# STM32U5G7xx register map
File version: 1.0
Registers are 32-bit, read-write, reset 0x0 unless marked. A register's access mark holds for its fields unless they carry their own. Offsets are from the block's base; [hi:lo] are bit positions; {n}, {i} and the like mark numbered series.

## TIM1 — TIM
Base 0x40012C00
Same registers: TIM1_S 0x50012C00
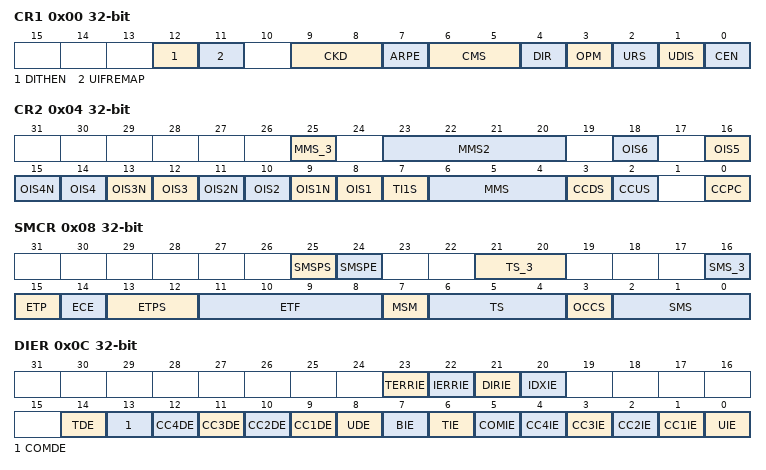
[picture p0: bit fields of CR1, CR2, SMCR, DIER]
0x00 CR1 — TIM control register 1
  [12] DITHEN — Dithering enable
  [11] UIFREMAP — Update interrupt flag remap
  [9:8] CKD — CKD[1:0] bits (clock division)
    0=DIV1 (tDTS=tCK_INT); 1=DIV2 (tDTS=2*tCK_INT); 2=DIV4 (tDTS=4*tCK_INT)
  [7] ARPE — Auto-reload preload enable
  [6:5] CMS — CMS[1:0] bits (Center-aligned mode selection)
  [4] DIR — Direction
    0=UP (Timer counter counts up); 1=DOWN (Timer counter counts down)
  [3] OPM — One pulse mode
    1=SINGLE (Counter stops counting at the next update event); 0=REPETITIVE (Counter is not stopped at update event)
  [2] URS — Update request source
    0=REGULAR (Counter overflow/underflow, Setting the UG bit or Update generation through the slave mode controller generates an update request); 1=COUNTER (Only counter overflow/underflow generates an update request)
  [1] UDIS — Update disable
  [0] CEN — Counter enable
0x04 CR2 — TIM control register 2
  [25] MMS_3 — MMS[3:0] bits (Master Mode Selection)
  [23:20] MMS2 — MMS[2:0] bits (Master Mode Selection)
    0=RESET (UG bit from the TIMx_EGR register is used as trigger output 2); 1=ENABLE (Counter Enable signal (CNT_EN) is used as trigger output 2); 2=UPDATE (Update event is used as trigger output 2); 3=CC1F (CC1 capture or a compare match is used as trigger output 2); {v}=OC{v-3} (OC{v-3}REF signal is used as trigger output 2) (v=4..9); 10=OC4_RISINGFALLING (OC4REF rising or falling edges are used as trigger output 2); 11=OC6_RISINGFALLING (OC6REF rising or falling edges are used as trigger output 2); 12=OC4_RISING_OC6_RISING (OC4REF or OC6REF rising edges are used as trigger output 2); 13=OC4_RISING_OC6_FALLING (OC4REF rising or OC6REF falling edges are used as trigger output 2); 14=OC5_RISING_OC6_RISING (OC5REF or OC6REF rising edges are used as trigger output 2); 15=OC5_RISING_OC6_FALLING (OC5REF rising or OC6REF falling edges are used as trigger output 2)
  [2n+6] OIS{n} (n=1..6) — Output Idle state {n} (OC{n} output)
  [2n+7] OIS{n}N (n=1..4) — Output Idle state {n} (OC{n}N output)
  [7] TI1S — TI1 Selection
  [6:4] MMS — MMS[3:0] bits (Master Mode Selection)
  [3] CCDS — Capture/Compare DMA Selection
    0=CC (CCx DMA request sent when CCx event occurs); 1=UPDATE (CCx DMA requests sent when update event occurs)
  [2] CCUS — Capture/Compare Control Update Selection
    0=ONLY (Capture/compare control bits are updated by setting the COMG bit only); 1=AND_TRGI (Capture/compare control bits are updated by setting the COMG bit or when a rising edge occurs on trigger input (TRGI))
  [0] CCPC — Capture/Compare Preloaded Control
0x08 SMCR — TIM slave mode control register
  [25] SMSPS — SMS preload source
    0=TIMUPDATE (The SMS preload transfer is triggered by the Timer's Update event); 1=INDEX (The SMS preload transfer is triggered by the Index event)
  [24] SMSPE — SMS preload enable
  [21:20] TS_3 — TS[2:0] bits (Trigger selection)
  [16] SMS_3 — SMS[2:0] bits (Slave mode selection)
  [15] ETP — External trigger polarity
  [14] ECE — External clock enable
  [13:12] ETPS — ETPS[1:0] bits (External trigger prescaler)
  [11:8] ETF — ETF[3:0] bits (External trigger filter)
  [7] MSM — Master/slave mode
  [6:4] TS — TS[2:0] bits (Trigger selection)
  [3] OCCS — OCREF clear selection
  [2:0] SMS — SMS[2:0] bits (Slave mode selection)
0x0C DIER — TIM DMA/interrupt enable register
  [23] TERRIE — Encoder transition error enable
  [22] IERRIE — Encoder index error enable
  [21] DIRIE — Encoder direction change interrupt enable
  [20] IDXIE — Encoder index interrupt enable
  [14] TDE — Trigger DMA request enable
  [13] COMDE — COM DMA request enable
  [n+8] CC{n}DE (n=1..4) — Capture/Compare {n} DMA request enable
  [8] UDE — Update DMA request enable
  [7] BIE — Break interrupt enable
  [6] TIE — Trigger interrupt enable
  [5] COMIE — COM interrupt enable
  [n] CC{n}IE (n=1..4) — Capture/Compare {n} interrupt enable
  [0] UIE — Update interrupt enable
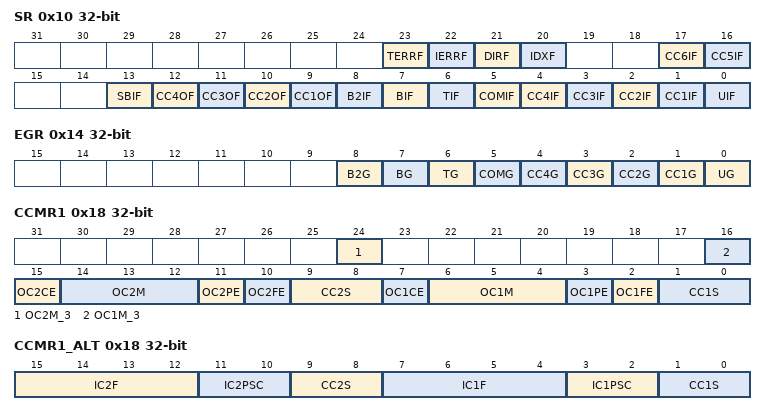
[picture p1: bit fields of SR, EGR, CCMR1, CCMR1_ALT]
0x10 SR — TIM status register
  [23] TERRF — Encoder transition error flag
  [22] IERRF — Encoder index error flag
  [21] DIRF — Encoder direction change interrupt flag
  [20] IDXF — Encoder index interrupt flag
  [17] CC6IF — Capture/Compare 6 interrupt Flag
  [16] CC5IF — Capture/Compare 5 interrupt Flag
  [13] SBIF — System Break interrupt Flag
  [n+8] CC{n}OF (n=1..4) — Capture/Compare {n} Overcapture Flag
  [8] B2IF — Break 2 interrupt Flag
  [7] BIF — Break interrupt Flag
  [6] TIF — Trigger interrupt Flag
  [5] COMIF — COM interrupt Flag
  [n] CC{n}IF (n=1..4) — Capture/Compare {n} interrupt Flag
  [0] UIF — Update interrupt Flag
0x14 EGR — TIM event generation register
  [8] B2G — Break 2 Generation
  [7] BG — Break Generation
  [6] TG — Trigger Generation
  [5] COMG — Capture/Compare Control Update Generation
  [n] CC{n}G (n=1..4) — Capture/Compare {n} Generation
  [0] UG — Update Generation
0x18 CCMR1 — TIM capture/compare mode register 1
  [24] OC2M_3 — OC2M[2:0] bits (Output Compare 2 Mode)
  [16] OC1M_3 — OC1M[2:0] bits (Output Compare 1 Mode)
  [15] OC2CE — Output Compare 2 Clear Enable
  [14:12] OC2M — OC2M[2:0] bits (Output Compare 2 Mode)
  [11] OC2PE — Output Compare 2 Preload enable
  [10] OC2FE — Output Compare 2 Fast enable
  [9:8] CC2S — CC2S[1:0] bits (Capture/Compare 2 Selection)
  [7] OC1CE — Output Compare 1 Clear Enable
  [6:4] OC1M — OC1M[2:0] bits (Output Compare 1 Mode)
  [3] OC1PE — Output Compare 1 Preload enable
  [2] OC1FE — Output Compare 1 Fast enable
  [1:0] CC1S — CC1S[1:0] bits (Capture/Compare 1 Selection)
0x18 CCMR1_ALT (alternate view of CCMR1) — TIM capture/compare mode register 1
  [15:12] IC2F — IC2F[3:0] bits (Input Capture 2 Filter)
  [11:10] IC2PSC — IC2PSC[1:0] bits (Input Capture 2 Prescaler)
  [9:8] CC2S — CC2S[1:0] bits (Capture/Compare 2 Selection)
  [7:4] IC1F — IC1F[3:0] bits (Input Capture 1 Filter)
  [3:2] IC1PSC — IC1PSC[1:0] bits (Input Capture 1 Prescaler)
  [1:0] CC1S — CC1S[1:0] bits (Capture/Compare 1 Selection)
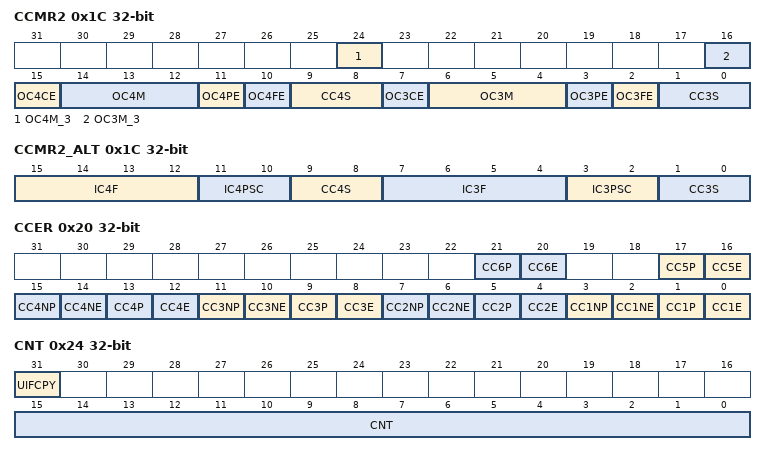
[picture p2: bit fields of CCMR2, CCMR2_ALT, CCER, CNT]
0x1C CCMR2 — TIM capture/compare mode register 2
  [24] OC4M_3 — OC4M[2:0] bits (Output Compare 4 Mode)
  [16] OC3M_3 — OC3M[2:0] bits (Output Compare 3 Mode)
  [15] OC4CE — Output Compare 4 Clear Enable
  [14:12] OC4M — OC4M[2:0] bits (Output Compare 4 Mode)
  [11] OC4PE — Output Compare 4 Preload enable
  [10] OC4FE — Output Compare 4 Fast enable
  [9:8] CC4S — CC4S[1:0] bits (Capture/Compare 4 Selection)
  [7] OC3CE — Output Compare 3 Clear Enable
  [6:4] OC3M — OC3M[2:0] bits (Output Compare 3 Mode)
  [3] OC3PE — Output Compare 3 Preload enable
  [2] OC3FE — Output Compare 3 Fast enable
  [1:0] CC3S — CC3S[1:0] bits (Capture/Compare 3 Selection)
0x1C CCMR2_ALT (alternate view of CCMR2) — TIM capture/compare mode register 2
  [15:12] IC4F — IC4F[3:0] bits (Input Capture 4 Filter)
  [11:10] IC4PSC — IC4PSC[1:0] bits (Input Capture 4 Prescaler)
  [9:8] CC4S — CC4S[1:0] bits (Capture/Compare 4 Selection)
  [7:4] IC3F — IC3F[3:0] bits (Input Capture 3 Filter)
  [3:2] IC3PSC — IC3PSC[1:0] bits (Input Capture 3 Prescaler)
  [1:0] CC3S — CC3S[1:0] bits (Capture/Compare 3 Selection)
0x20 CCER — TIM capture/compare enable register
  [4n-3] CC{n}P (n=1..6) — Capture/Compare {n} output Polarity
  [4n-4] CC{n}E (n=1..6) — Capture/Compare {n} output enable
  [4n-1] CC{n}NP (n=1..4) — Capture/Compare {n} Complementary output Polarity
  [4n-2] CC{n}NE (n=1..4) — Capture/Compare {n} Complementary output enable
0x24 CNT — TIM counter register
  [31] UIFCPY — Update interrupt flag copy (if UIFREMAP=1)
  [15:0] CNT — Counter Value
0x28 PSC — TIM prescaler
  [15:0] PSC — Prescaler Value
0x2C ARR — TIM auto-reload register
  [15:0] ARR — Actual auto-reload Value
0x30 RCR — TIM repetition counter register
  [15:0] REP — Repetition Counter Value
{0x30+4i} CCR{i} (i=1..4) — TIM capture/compare register {i}
  [15:0] CCR{i} — Capture/Compare {i} Value
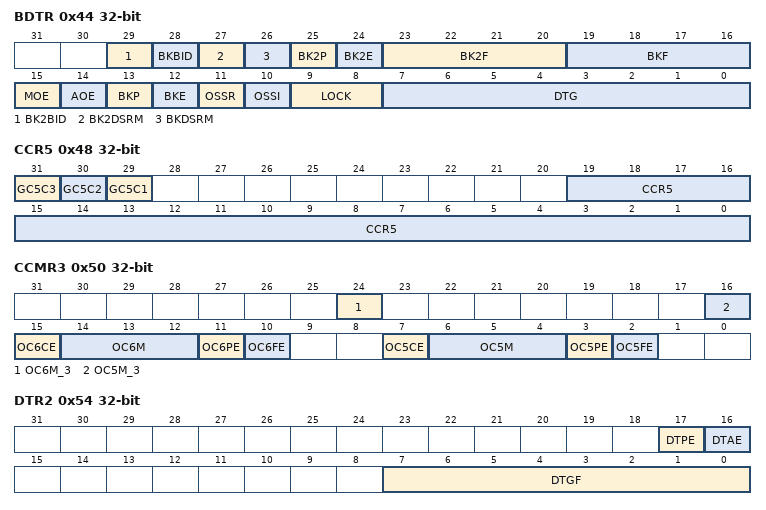
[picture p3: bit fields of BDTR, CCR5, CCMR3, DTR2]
0x44 BDTR — TIM break and dead-time register
  [29] BK2BID — Break2 BIDirectional
  [28] BKBID — Break BIDirectional
  [27] BK2DSRM — Break2 disarming/re-arming
  [26] BKDSRM — Break disarming/re-arming
  [25] BK2P — Break Polarity for Break 2
  [24] BK2E — Break enable for Break 2
  [23:20] BK2F — Break Filter for Break 2
  [19:16] BKF — Break Filter for Break 1
  [15] MOE — Main Output enable
  [14] AOE — Automatic Output enable
  [13] BKP — Break Polarity for Break 1
  [12] BKE — Break enable for Break 1
  [11] OSSR — Off-State Selection for Run mode
  [10] OSSI — Off-State Selection for Idle mode
  [9:8] LOCK — LOCK[1:0] bits (Lock Configuration)
    0=OFF (LOCK OFF - No bit is write protected); 1=LOCKLEVEL_1; 2=LOCKLEVEL_2; 3=LOCKLEVEL_3
  [7:0] DTG — DTG[0:7] bits (Dead-Time Generator set-up)
0x48 CCR5 — TIM capture/compare register 5
  [31] GC5C3 — Group Channel 5 and Channel 3
  [30] GC5C2 — Group Channel 5 and Channel 2
  [29] GC5C1 — Group Channel 5 and Channel 1
  [19:0] CCR5 — Capture/Compare 5 Value
0x4C CCR6 — TIM capture/compare register 6
  [19:0] CCR6 — Capture/Compare 6 Value
0x50 CCMR3 — TIM capture/compare mode register 3
  [24] OC6M_3 — OC6M[3:0] bits (Output Compare 6 Mode)
  [16] OC5M_3 — OC5M[3:0] bits (Output Compare 5 Mode)
  [15] OC6CE — Output Compare 6 Clear Enable
  [14:12] OC6M — OC6M[3:0] bits (Output Compare 6 Mode)
  [11] OC6PE — Output Compare 6 Preload enable
  [10] OC6FE — Output Compare 6 Fast enable
  [7] OC5CE — Output Compare 5 Clear Enable
  [6:4] OC5M — OC5M[3:0] bits (Output Compare 5 Mode)
  [3] OC5PE — Output Compare 5 Preload enable
  [2] OC5FE — Output Compare 5 Fast enable
0x54 DTR2 — TIM deadtime register 2
  [17] DTPE — Deadtime prelaod enable
  [16] DTAE — Deadtime asymmetric enable
  [7:0] DTGF — DTGF[7:0] bits (Deadtime falling edge generator setup)
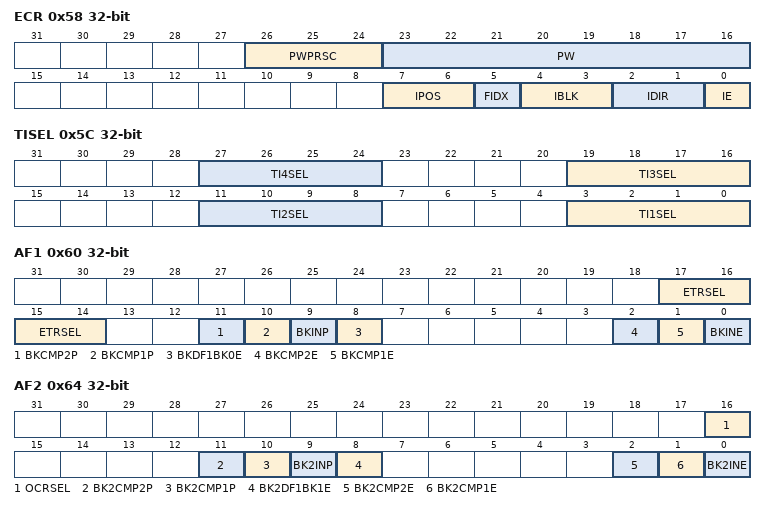
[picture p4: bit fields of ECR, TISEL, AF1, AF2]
0x58 ECR — TIM encoder control register
  [26:24] PWPRSC — PWPRSC[2:0] bits (Pulse width prescaler)
    0=Pulse on compare pulse width prescaler 1; 1=X2 (Pulse on compare pulse width prescaler 2); 2=X4 (Pulse on compare pulse width prescaler 4); 3=X8 (Pulse on compare pulse width prescaler 8); 4=X16 (Pulse on compare pulse width prescaler 16); 5=X32 (Pulse on compare pulse width prescaler 32); 6=X64 (Pulse on compare pulse width prescaler 64); 7=X128 (Pulse on compare pulse width prescaler 128)
  [23:16] PW — PW[7:0] bits (Pulse width)
  [7:6] IPOS — IPOS[1:0] bits (Index positioning)
    0=DOWN_DOWN (Index resets the counter when AB = 00); 1=DOWN_UP (Index resets the counter when AB = 01); 2=UP_DOWN (Index resets the counter when AB = 10); 3=UP_UP (Index resets the counter when AB = 11)
  [5] FIDX — First index enable
  [4:3] IBLK — IBLK[1:0] bits (Index blanking)
    0=ALWAYS (Index always active); 1=TI3 (Index disabled when TI3 input is active, as per CC3P bitfield); 2=TI4 (Index disabled when TI4 input is active, as per CC4P bitfield)
  [2:1] IDIR — IDIR[1:0] bits (Index direction)
    0=UP_DOWN (Index resets the counter whatever the direction); 1=UP (Index resets the counter when up-counting only); 2=DOWN (Index resets the counter when down-counting only)
  [0] IE — Index enable
0x5C TISEL — TIM Input Selection register
  [8n-5:8n-8] TI{n}SEL (n=1..4) — TI{n}SEL[3:0] bits (TIM1 TI{n} SEL)
0x60 AF1 — TIM alternate function option register 1
  [17:14] ETRSEL — ETRSEL[3:0] bits (TIM1 ETR source selection)
  [11] BKCMP2P — BRK COMP2 input polarity
  [10] BKCMP1P — BRK COMP1 input polarity
  [9] BKINP — BRK BKIN input polarity
  [8] BKDF1BK0E — BRK mdf1_break[0](TIM1) or mdf1_break[2](TIM2) enable
  [2] BKCMP2E — BRK COMP2 enable
  [1] BKCMP1E — BRK COMP1 enable
  [0] BKINE — BRK BKIN input enable
0x64 AF2 — TIM alternate function option register 2
  [16] OCRSEL — OCREF_CLR source selection
  [11] BK2CMP2P — BRK2 COMP2 input polarity
  [10] BK2CMP1P — BRK2 COMP1 input polarity
  [9] BK2INP — BRK2 BKIN input polarity
  [8] BK2DF1BK1E — BRK2 mdf1_break[1](TIM1) or mdf1_break[3](TIM8) enable
  [2] BK2CMP2E — BRK2 COMP2 enable
  [1] BK2CMP1E — BRK2 COMP1 enable
  [0] BK2INE — BRK2 BKIN input enable
0x68 OR1 — TIM option register
  [1] HSE32EN — HSE/32 clock enable
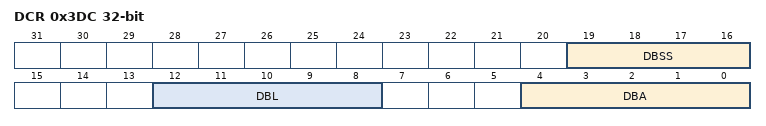
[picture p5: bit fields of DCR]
0x3DC DCR — TIM DMA control register
  [19:16] DBSS — DBSS[19:16] bits (DMA Burst Source Selection)
  [12:8] DBL — DBL[4:0] bits (DMA Burst Length)
  [4:0] DBA — DBA[4:0] bits (DMA Base Address)
0x3E0 DMAR — TIM DMA address for full transfer
  [31:0] DMAB — DMA register for burst accesses

## TIM8 — TIM
Base 0x40013400
Same registers: TIM8_S 0x50013400
Registers as TIM1; these are added or differ:
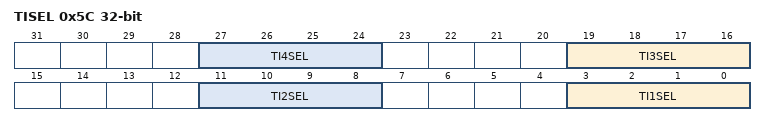
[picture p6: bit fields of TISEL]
0x5C TISEL — TIM Input Selection register
  [8n-5:8n-8] TI{n}SEL (n=1..4) — TI{n}SEL[3:0] bits (TIM1 TI{n} SEL)
0x60 AF1 — TIM alternate function option register 1
0x64 AF2 — TIM alternate function option register 2
